VERSION ""

NS_ :

BS_:

BU_: HVAC TPMS CLU BCM VCU

BO_ 791 TireCautionAlert: 1 CLU
 SG_ TireCautionAlertFlag : 0|1@1+ (1,0) [0|1] "Flag"  VCU

BO_ 768 StartUp: 1 VCU
 SG_ StartUpSignal : 0|1@1+ (1,0) [0|1] "Flag"  BCM,CLU,HVAC,TPMS

BO_ 790 CautionTurnInput: 1 CLU
 SG_ CautionTurnSignal : 0|1@1+ (1,0) [0|1] "Flag"  VCU

BO_ 789 RightTurnInput: 1 CLU
 SG_ RightTurnInputSignal : 0|1@1+ (1,0) [0|1] "Flag"  VCU

BO_ 788 LeftTurnInput: 1 CLU
 SG_ LeftTurnInputSignal : 0|1@1+ (1,0) [0|1] "Flag"  VCU

BO_ 784 IgnitionOn: 1 CLU
 SG_ IgnitionFlag : 0|1@1+ (1,0) [0|1] "Flag"  VCU

BO_ 776 BrakeInputFlag: 1 VCU
 SG_ BrakeInputFlag : 0|1@1+ (1,0) [0|1] "Flag"  BCM

BO_ 770 DriveMode: 1 VCU
 SG_ DriveMode : 0|2@1+ (1,0) [0|2] "Flag"  BCM

BO_ 816 GearInput: 1 BCM
 SG_ GearInput : 0|2@1+ (1,0) [0|3] "level"  CLU,VCU

BO_ 787 ADSOperation: 1 CLU
 SG_ ADSOperation : 0|2@1+ (1,0) [0|2] "level"  HVAC

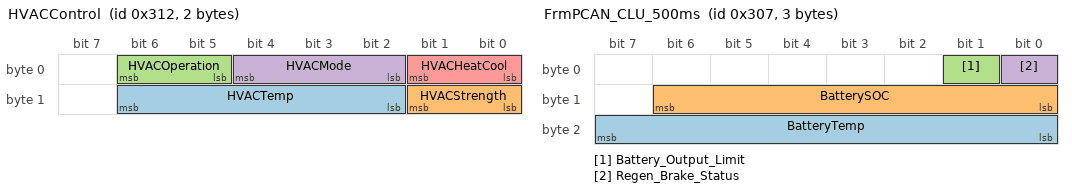
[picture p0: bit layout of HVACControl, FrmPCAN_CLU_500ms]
BO_ 786 HVACControl: 2 CLU
 SG_ HVACTemp : 10|5@1+ (1,18) [18|32] "degree"  HVAC
 SG_ HVACStrength : 8|2@1+ (1,0) [0|2] "level"  HVAC
 SG_ HVACOperation : 5|2@1+ (1,0) [0|1] "Flag"  HVAC
 SG_ HVACMode : 2|3@1+ (1,0) [0|7] "level"  HVAC
 SG_ HVACHeatCool : 0|2@1+ (1,0) [0|2] "Flag"  HVAC

BO_ 820 RRTurnVoltCurrent: 1 BCM
 SG_ RRVolt : 5|3@1+ (1,0) [0|5] "V"  VCU
 SG_ RRCurrent : 0|5@1+ (1,0) [0|30] "mA"  VCU

BO_ 819 RLTurnVoltCurrent: 1 BCM
 SG_ RLVolt : 5|3@1+ (1,0) [0|5] "V"  VCU
 SG_ RLCurrent : 0|5@1+ (1,0) [0|30] "mA"  VCU

BO_ 818 FRTurnVoltCurrent: 1 BCM
 SG_ FRVolt : 5|3@1+ (1,0) [0|5] "V"  VCU
 SG_ FRCurrent : 0|5@1+ (1,0) [0|30] "mA"  VCU

BO_ 817 FLTurnVoltCurrent: 1 BCM
 SG_ FLVolt : 5|3@1+ (1,0) [0|5] "V"  VCU
 SG_ FLCurrent : 0|5@1+ (1,0) [0|30] "mA"  VCU

BO_ 775 FrmPCAN_CLU_500ms: 3 VCU
 SG_ BatteryTemp : 16|8@1- (1,90) [-50|150] "degree"  CLU
 SG_ BatterySOC : 8|7@1+ (1,0) [0|100] "percent"  CLU
 SG_ Battery_Output_Limit : 1|1@1+ (1,0) [0|1] "Flag"  CLU
 SG_ Regen_Brake_Status : 0|1@1+ (1,0) [0|1] "Flag"  CLU

BO_ 771 FrmVCU_CLU_100ms: 1 VCU
 SG_ CurVelocity : 0|8@1+ (1,0) [0|250] "km/h"  BCM,CLU

BO_ 800 TirePressureAlert: 1 TPMS
 SG_ TireAlertFlag : 0|1@1+ (1,0) [0|1] "Flag"  VCU,CLU

BO_ 785 RegBrake_level: 1 CLU
 SG_ RegBrake_Level : 0|2@1+ (1,0) [0|3] "stage"  VCU,CLU

BO_ 774 RightTurnSignalLampControl: 2 VCU
 SG_ RightTurnSignalPeriod : 0|10@1+ (1,0) [0|1000] "ms"  BCM
 SG_ RightTurnSignalControl : 15|1@1+ (1,0) [0|1] "Flag"  BCM

BO_ 773 LeftTurnSignalLampControl: 2 VCU
 SG_ LeftTurnSignalPeriod : 0|10@1+ (1,0) [0|1000] "ms"  BCM
 SG_ LeftTurnSignalControl : 15|1@1+ (1,0) [0|1] "Flag"  BCM

BO_ 772 CautionLampControl: 2 VCU
 SG_ CautionLampPeriod : 0|10@1+ (1,0) [0|1000] "ms"  BCM
 SG_ CautionLampControl : 15|1@1+ (1,0) [0|1] "Flag"  BCM

BO_ 804 TireStateRR: 3 TPMS
 SG_ WheelRRTemp : 16|7@1- (1,30) [-30|85] "celcius degree"  VCU,CLU
 SG_ WheelRRPressure : 0|10@1+ (1,0) [0|600] "bar"  VCU,CLU

BO_ 803 TireStateRL: 3 TPMS
 SG_ WheelRLTemp : 16|7@1- (1,30) [-30|85] "celcius degree"  VCU,CLU
 SG_ WheelRLPressure : 0|10@1+ (1,0) [0|600] "bar"  VCU,CLU

BO_ 802 TireStateFR: 3 TPMS
 SG_ WheelFRTemp : 16|7@1- (1,30) [-30|85] "celcius degree"  VCU,CLU
 SG_ WheelFRPressure : 0|10@1+ (1,0) [0|600] "bar"  VCU,CLU

BO_ 801 TireStateFL: 3 TPMS
 SG_ WheelFLTemp : 16|7@1- (1,30) [-30|85] "celcius degree"  VCU,CLU
 SG_ WheelFLPressure : 0|10@1+ (1,0) [0|600] "bar"  VCU,CLU

BA_DEF_  "BusType" STRING ;
BA_DEF_DEF_  "BusType" "CAN";
